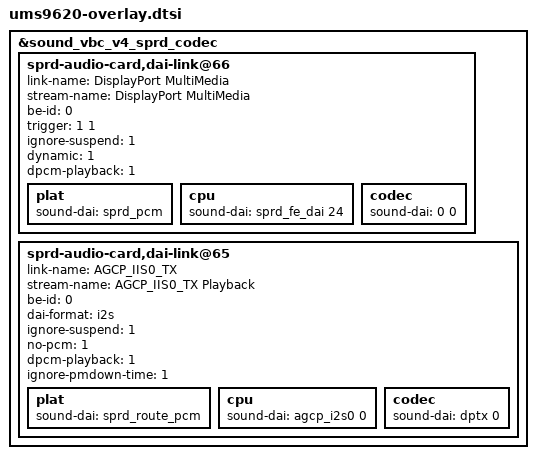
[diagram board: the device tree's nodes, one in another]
// SPDX-License-Identifier: (Licenseref-Unisoc-General-1.0 OR GPL-2.0-only)
/*
 * ums9620-overlay.dtsi - Unisoc platform device
 *
 * Copyright 2023 Unisoc(Shanghai) Technologies Co.Ltd
 *
 * Licensed under the Unisoc General Software License, version 1.0 (the
 * License);
 * you may not use this file except in compliance with the License.
 * You may obtain a copy of the License at
 * https://www.unisoc.com/en_us/license/UNISOC_GENERAL_LICENSE_V1.0-EN_US
 * Software distributed under the License is distributed on an "AS IS" BASIS,
 * WITHOUT WARRANTIES OF ANY KIND, either express or implied.
 * See the Unisoc General Software License, version 1.0 for more details.
 *
 * Alternatively you can use and distribute this file under the terms of the
 * GNU General Public License version 2, provided that it has to be used
 *  (including but not limited to combining, linking) with any other file under
 * the GNU General Public License version 2 on platforms that use Unisoc Chips.
 */

&sound_vbc_v4_sprd_codec {
	status = "okay";

	/* 24: fe DisplayPort pcm */
	sprd-audio-card,dai-link@66 {
		link-name = "DisplayPort MultiMedia";
		stream-name = "DisplayPort MultiMedia";
		be-id = <0>;
		trigger = <1 1>;
		ignore-suspend = <1>;
		dynamic = <1>;
		dpcm-playback = <1>;
		plat {
			sound-dai = <&sprd_pcm>;
		};
		cpu {
			sound-dai = <&sprd_fe_dai 24>;
		};
		codec {
			sound-dai = <0 0>;
		};
	};

	/* agcp_i2s0: be dp pcm */
	sprd-audio-card,dai-link@65 {
		link-name = "AGCP_IIS0_TX";
		stream-name = "AGCP_IIS0_TX Playback";
		be-id = <0>;
		dai-format = "i2s";
		ignore-suspend = <1>;
		no-pcm = <1>;
		dpcm-playback = <1>;
		ignore-pmdown-time = <1>;
		plat {
			sound-dai = <&sprd_route_pcm>;
		};
		cpu {
			sound-dai = <&agcp_i2s0 0>;
		};
		codec {
			sound-dai = <&dptx 0>;
		};
	};
};
